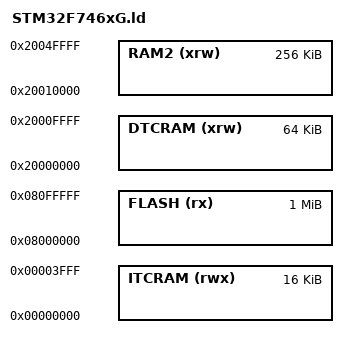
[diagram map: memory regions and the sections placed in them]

MEMORY
{
  FLASH (rx) :    ORIGIN = 0x08000000, LENGTH = 1024K

  ITCRAM (rwx) :  ORIGIN = 0x00000000, LENGTH = 16K
  DTCRAM (xrw) :  ORIGIN = 0x20000000, LENGTH = 64K
  RAM2 (xrw) :    ORIGIN = 0x20010000, LENGTH = 256K
}

REGION_ALIAS("TEXT", FLASH);
REGION_ALIAS("RAM", RAM2);

INCLUDE nvcm_default_flash.ld

